VERSION "HIPBYYYYYYYYYYYYYYYYYYYYYYYYYYYYYYYYYNNNNN/4/%%%/4/'%**4YYN///"

BS_:

BU_: Vin

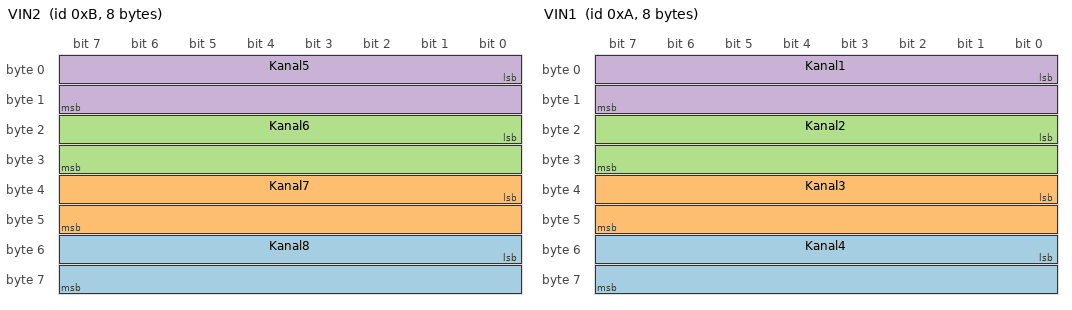
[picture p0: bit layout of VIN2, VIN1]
BO_ 11 VIN2: 8 Vin
 SG_ Kanal8 : 48|16@1- (0.0009155,0) [-30|30] "Volt" Vector__XXX
 SG_ Kanal7 : 32|16@1- (0.0009155,0) [-30|30] "Volt" Vector__XXX
 SG_ Kanal6 : 16|16@1- (0.0009155,0) [-30|30] "Volt" Vector__XXX
 SG_ Kanal5 : 0|16@1- (0.0009155,0) [-30|30] "Volt" Vector__XXX

BO_ 10 VIN1: 8 Vin
 SG_ Kanal4 : 48|16@1- (0.0009155,0) [-30|30] "Volt" Vector__XXX
 SG_ Kanal3 : 32|16@1- (0.0009155,0) [-30|30] "Volt" Vector__XXX
 SG_ Kanal2 : 16|16@1- (0.0009155,0) [-30|30] "Volt" Vector__XXX
 SG_ Kanal1 : 0|16@1- (0.0009155,0) [-30|30] "Volt" Vector__XXX
